# CY8C4247AZI_M485 register map
File version: 0.1
PSoC 4200M
Registers are 32-bit, read-write, no defined reset value unless marked. A register's access mark holds for its fields unless they carry their own. Offsets are from the block's base; lines under a group give offsets from that group; [hi:lo] are bit positions; {n}, {i} and the like mark numbered series; 'fields as' and 'values as' point back to an identical list; <NAME> marks a mode.

## Memory map
0x00000000 SENSOR_1 — Serial Communication Block
0x00000000 SENSOR_2 — Serial Communication Block
0x00000000 SENSOR_3 — Serial Communication Block
0x00000000 RX — UART
0x00000000 DMAC — DMAC Registers
0x00000000 SENSOR_4 — Serial Communication Block
0x00000000 CAN
0x00000000 TXC
0x00000000 MOTOR — UART

## RX — UART
Base 0x00000000
0x400F0022 RX_RX_RX_ADDRESS1 8-bit — RX Address1 Register
0x400F0032 RX_RX_RX_ADDRESS2 8-bit — RX Address2 Register
0x400F0042 RX_RX_RX_DATA 8-bit — RX Data Register
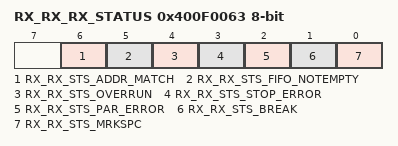
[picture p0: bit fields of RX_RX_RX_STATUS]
0x400F0063 RX_RX_RX_STATUS 8-bit — RX status register
  [6] RX_RX_STS_ADDR_MATCH ro, [5] RX_RX_STS_FIFO_NOTEMPTY ro, [4] RX_RX_STS_OVERRUN ro, [3] RX_RX_STS_STOP_ERROR ro, [2] RX_RX_STS_PAR_ERROR ro, [1] RX_RX_STS_BREAK ro, [0] RX_RX_STS_MRKSPC ro

## TXC
Base 0x00000000
0x400F0071 TXC_CONTROL_REG 8-bit

## MOTOR — UART
Base 0x00000000
0x400F0041 TX_MOTOR_TX_DATA 8-bit — TX Data Register
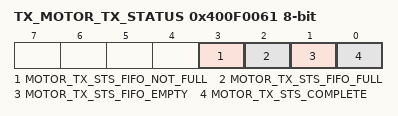
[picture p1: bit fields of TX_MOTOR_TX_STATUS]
0x400F0061 TX_MOTOR_TX_STATUS 8-bit — TX status register
  [3] MOTOR_TX_STS_FIFO_NOT_FULL ro, [2] MOTOR_TX_STS_FIFO_FULL ro, [1] MOTOR_TX_STS_FIFO_EMPTY ro, [0] MOTOR_TX_STS_COMPLETE ro

## CAN
Base 0x00000000
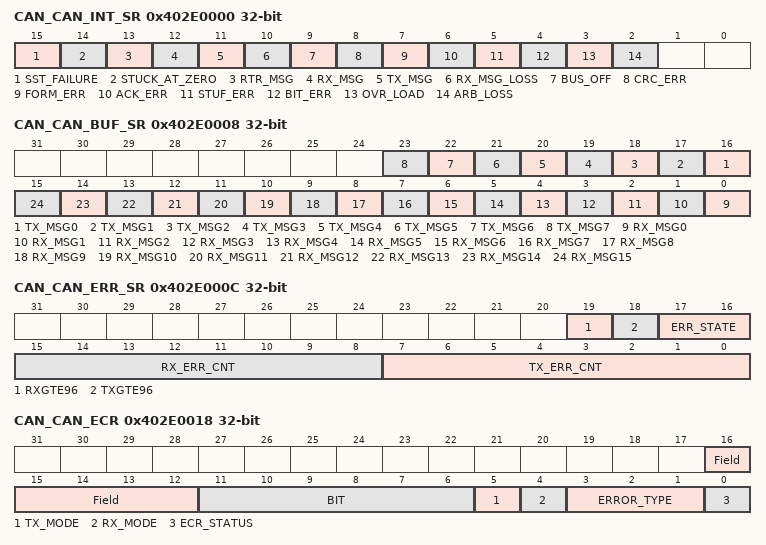
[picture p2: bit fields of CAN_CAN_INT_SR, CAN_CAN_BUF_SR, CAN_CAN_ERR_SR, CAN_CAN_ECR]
0x402E0000 CAN_CAN_INT_SR — The interrupt status register stores internal interrupt events. ? Once a bit is set it remains set until it is cleared by writing a '1' to it. ? The interrupt enable register has no effect on the interrupt status register. ? A pending interrupt occurs when the flag is set to '1'. To acknowledge an interrupt, set the flag to '1'
  [15] SST_FAILURE — Single shot transmission failure
  [14] STUCK_AT_ZERO — Stuck at dominant error
  [13] RTR_MSG — RTR auto-reply message sent
  [12] RX_MSG — Msg Recieved
  [11] TX_MSG — Tx msg Sent
  [10] RX_MSG_LOSS — Rx msg loss Interrupt
  [9] BUS_OFF — Bus Off State
  [8] CRC_ERR — CRC Error Interrupt
  [7] FORM_ERR — Form Error Interrupt
  [6] ACK_ERR — Ack Error Interrupt
  [5] STUF_ERR — Stuff Error Interrupt
  [4] BIT_ERR — Bit Error Interrupt
  [3] OVR_LOAD — Overload Interrupt
  [2] ARB_LOSS — Arbitration Loss
0x402E0008 CAN_CAN_BUF_SR — These status indicators bundle the respective flags from all RxMessage and TxMessage buffers. ? Note All flags are read only. To acknowledge a MsgAv flag, the CPU must write to the respective RxMessage buffer
  [n+16] TX_MSG{n} (n=0..7) — Tx req Pending for Tx Msg{n}
  [n] RX_MSG{n} (n=0..15) — Rx Msg{n} Available
0x402E000C CAN_CAN_ERR_SR — Status indicators are provided to report the CAN controller error state, receive error count, and transmit error count. ? Special flags report error counter values equal to or in excess of 96 errors are available to indicate heavily disturbed bus situations. ? The transmitter error counter according to the CAN standard. When it is greater than 255 Decimal, it is fixed at 255 Decimal.
  [19] RXGTE96 — Rx Error Count is greater or equal to 96 Decimal
  [18] TXGTE96 — Tx Error Count is greater or equal to 96 Decimal
  [17:16] ERR_STATE — Error State of CAN node, 00 error active, 01 error passive, 1x bus off
  [15:8] RX_ERR_CNT — Rx error Count. When in bus-off state,this counter is used to count 128 groups of 11 recessive bits
  [7:0] TX_ERR_CNT — Tx error Count
0x402E0018 CAN_CAN_ECR — The Error Capture register operates in two different modes: ? Free running mode - ECR displays the fiels and bit positions within the current CAN frame ? Error Capture mode - ECR samples the field and bit position when a CAN error is detected ? In order to sample such an event, the ECR needs to be armed by performing a write access to it. ? When armed, the ECR only captures one error event. ? For successive error captures, the ECR needs to be armed again.
  [16:12] Field ro — Field: ? 0x00 : Stopped ? 0x01 : Synchronize ? 0x05 : Interframe ? 0x06 : Bus Idle ? 0x07 : Start of Frame ? 0x08 : Arbitration ? 0x09 : Control ? 0x0A : Data ? 0x0B : CRC ? 0x0C : ACK ? 0x0D : End of frame ? 0x10 : Error flag ? 0x11 : Error echo ? 0x12 : Error delimiter ? 0x18 : Overload flag ? 0x19 : Overload echo ? 0x1A : Overload delimiter ? Others : N/A
  [11:6] BIT ro — Bit number inside of Field
  [5] TX_MODE ro — TX Mode: ? 0: No status ? 1: CAN Controller is transmitter
  [4] RX_MODE ro — RX Mode: ? 0: No status ? 1: CAN Controller is receiver
  [3:1] ERROR_TYPE ro — Error type: ? 000 : Arbitration loss ? 001 : Bit Error ? 010 : Bit Stuffing Error ? 011 : Acknowledge Error ? 100 : Form Error ? 101 : CRC Error ? Others : N/A
  [0] ECR_STATUS — ECR STATUS: ? 0: ECR register captured an error, or it is in free running mode ? 1: ECR register is armed
{0x402E0024+0x10*i} CAN_CAN_TX{i}_ID (i=0..7) — CAN Tx Msg Identifier
  [31:3] ID — Tx Msg Indentifier
{0x402E0028+0x10*i} CAN_CAN_TX{i}_DH (i=0..7) — CAN Tx Msg Upper Data Bytes
  [31:0] DATA_HIGH — Upper Data Bytes
{0x402E002C+0x10*i} CAN_CAN_TX{i}_DL (i=0..7) — CAN Tx Msg Lower Data Bytes
  [31:0] DATA_LOW — Lower Data Bytes
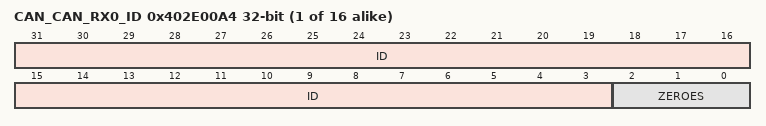
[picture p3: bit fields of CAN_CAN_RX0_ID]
{0x402E00A4+0x20*i} CAN_CAN_RX{i}_ID (i=0..15) — The register contains Rx Msg Identifier
  [31:3] ID — Rx Msg Indentifier
  [2:0] ZEROES — zeros
{0x402E00A8+0x20*i} CAN_CAN_RX{i}_DH (i=0..15) — The register contains the Rx Msg Upper Data Bytes
  [31:0] DATA_HIGH — Upper Data Bytes
{0x402E00AC+0x20*i} CAN_CAN_RX{i}_DL (i=0..15) — The register contains the Rx Msg Lover Data Bytes
  [31:0] DATA_LOW — Lower Data Bytes
